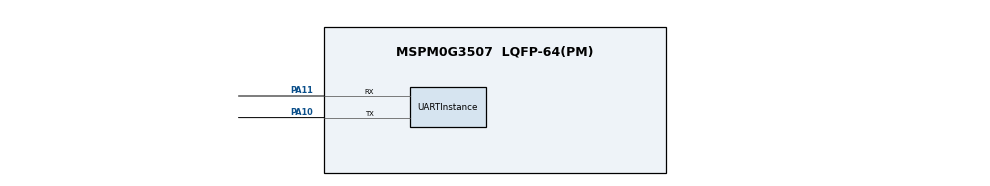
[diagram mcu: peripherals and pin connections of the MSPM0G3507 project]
/** TEST ONLY：TMP6131 ADC_DMA + XDS110 Backchannel UART CSV。 */
//@cliArgs --device "MSPM0G350X" --package "LQFP-64(PM)" --part "Default"
//@v2CliArgs --device "MSPM0G3507" --package "LQFP-64(PM)"
// @cliArgs --board /ti/boards/LP_MSPM0G3507 --rtos nortos

const Board = scripting.addModule("/ti/driverlib/Board");
const SYSCTL = scripting.addModule("/ti/driverlib/SYSCTL");
const ADC12 = scripting.addModule("/ti/driverlib/ADC12", {}, false);
const ADC12Instance = ADC12.addInstance();
const TIMER = scripting.addModule("/ti/driverlib/TIMER", {}, false);
const TIMERInstance = TIMER.addInstance();
const UART = scripting.addModule("/ti/driverlib/UART", {}, false);
const UARTInstance = UART.addInstance();

ADC12Instance.$name = "SIGNAL_ADC";
ADC12Instance.sampClkSrc = "DL_ADC12_CLOCK_ULPCLK";
ADC12Instance.adcMem0chansel = "DL_ADC12_INPUT_CHAN_5";
/* TI thermistor 示例使用约 3.25 us，给 10 kΩ 分压源充分建立时间。 */
ADC12Instance.sampleTime0 = "3.25 us";
ADC12Instance.powerDownMode = "DL_ADC12_POWER_DOWN_MODE_MANUAL";
ADC12Instance.trigSrc = "DL_ADC12_TRIG_SRC_EVENT";
/* Keep ADC armed, but require one new Timer event for each conversion. */
ADC12Instance.repeatMode = true;
ADC12Instance.adcMem0trig = "DL_ADC12_TRIGGER_MODE_TRIGGER_NEXT";
ADC12Instance.subChanID = 1;
ADC12Instance.configureDMA = true;
ADC12Instance.sampCnt = 1;
ADC12Instance.enabledDMATriggers = ["DL_ADC12_DMA_MEM0_RESULT_LOADED"];
ADC12Instance.enabledInterrupts = ["DL_ADC12_INTERRUPT_DMA_DONE"];
ADC12Instance.peripheral.$assign = "ADC0";
ADC12Instance.peripheral.adcPin5.$assign = "PB24";
ADC12Instance.DMA_CHANNEL.$name = "SIGNAL_ADC_DMA";
ADC12Instance.DMA_CHANNEL.peripheral.$assign = "DMA_CH0";
ADC12Instance.DMA_CHANNEL.addressMode = "f2b";
ADC12Instance.DMA_CHANNEL.srcLength = "HALF_WORD";
ADC12Instance.DMA_CHANNEL.dstLength = "HALF_WORD";
ADC12Instance.DMA_CHANNEL.transferMode = "SINGLE";

TIMERInstance.$name = "SIGNAL_SAMPLE_TIMER";
TIMERInstance.timerClkSrc = "BUSCLK";
TIMERInstance.timerClkDiv = 1;
TIMERInstance.timerClkPrescale = 1;
TIMERInstance.timerPeriod = "10us";
TIMERInstance.timerMode = "PERIODIC";
TIMERInstance.event1PublisherChannel = 1;
TIMERInstance.event1ControllerInterruptEn = ["ZERO_EVENT"];
TIMERInstance.peripheral.$assign = "TIMG0";

UARTInstance.$name = "UART_0";
UARTInstance.profile = "CONFIG_PROFILE_1";
UARTInstance.peripheral.$assign = "UART0";
UARTInstance.uartClkSrc = "BUSCLK";
UARTInstance.targetBaudRate = 115200;
UARTInstance.enableInternalLoopback = false;
UARTInstance.enableFIFO = true;
UARTInstance.peripheral.txPin.$assign = "PA10";
UARTInstance.peripheral.rxPin.$assign = "PA11";

SYSCTL.forceDefaultClkConfig = true;
SYSCTL.clockTreeEn = true;
